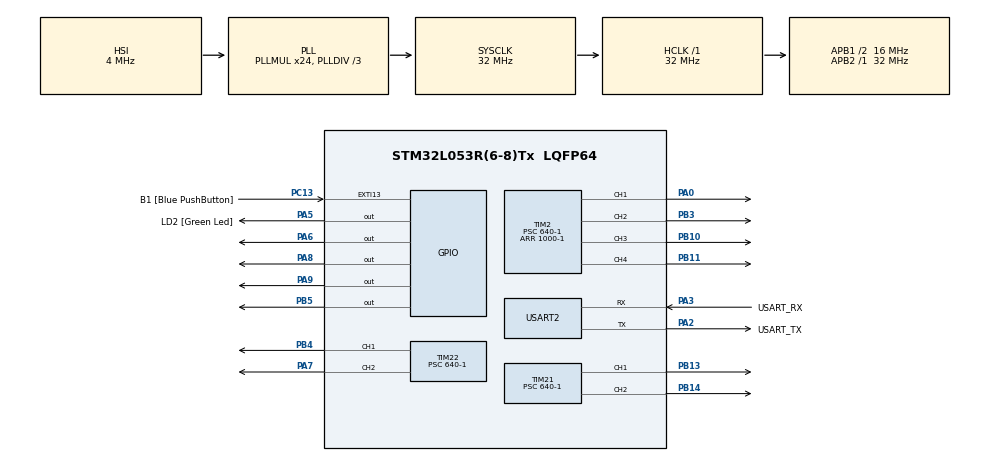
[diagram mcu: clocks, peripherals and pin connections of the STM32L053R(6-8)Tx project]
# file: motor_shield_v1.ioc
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Dma.Request0=USART2_RX
Dma.USART2_RX.0.Direction=DMA_PERIPH_TO_MEMORY
Dma.USART2_RX.0.Instance=DMA1_Channel5
Dma.USART2_RX.0.MemDataAlignment=DMA_MDATAALIGN_BYTE
Dma.USART2_RX.0.MemInc=DMA_MINC_ENABLE
Dma.USART2_RX.0.Mode=DMA_NORMAL
Dma.USART2_RX.0.PeriphDataAlignment=DMA_PDATAALIGN_BYTE
Dma.USART2_RX.0.PeriphInc=DMA_PINC_DISABLE
Dma.USART2_RX.0.Priority=DMA_PRIORITY_LOW
Mcu.Family=STM32L0
Mcu.Name=STM32L053R(6-8)Tx
Mcu.Package=LQFP64
NVIC.DMA1_Channel4_5_6_7_IRQn=true\:0\:0\:false\:false\:true\:false\:true\:true
NVIC.USART2_IRQn=true\:0\:0\:false\:false\:true\:true\:true\:true
PA0.Signal=S_TIM2_CH1
PA13.GPIO_Label=TMS
PA13.Mode=Serial_Wire
PA13.Signal=SYS_SWDIO
PA14.GPIO_Label=TCK
PA14.Mode=Serial_Wire
PA14.Signal=SYS_SWCLK
PA2.GPIO_Label=USART_TX
PA2.Mode=Asynchronous
PA2.Signal=USART2_TX
PA3.GPIO_Label=USART_RX
PA3.Mode=Asynchronous
PA3.Signal=USART2_RX
PA5.GPIO_Label=LD2 [Green Led]
PA5.Signal=GPIO_Output
PA6.Signal=GPIO_Output
PA7.Signal=S_TIM22_CH2
PA8.Signal=GPIO_Output
PA9.Signal=GPIO_Output
PB10.Signal=S_TIM2_CH3
PB11.Signal=S_TIM2_CH4
PB13.Signal=S_TIM21_CH1
PB14.Signal=S_TIM21_CH2
PB3.Signal=S_TIM2_CH2
PB4.Signal=S_TIM22_CH1
PB5.Signal=GPIO_Output
PC13.GPIO_Label=B1 [Blue PushButton]
PC13.GPIO_ModeDefaultEXTI=GPIO_MODE_IT_FALLING
PC13.Signal=GPXTI13
PC14-OSC32_IN.Mode=LSE-External-Oscillator
PC14-OSC32_IN.Signal=RCC_OSC32_IN
PC15-OSC32_OUT.Mode=LSE-External-Oscillator
PC15-OSC32_OUT.Signal=RCC_OSC32_OUT
PH0-OSC_IN.Mode=HSE-External-Clock-Source
PH0-OSC_IN.Signal=RCC_OSC_IN
PH1-OSC_OUT.Signal=RCC_OSC_OUT
ProjectManager.HeapSize=0x200
ProjectManager.StackSize=0x800
ProjectManager.TargetToolchain=MDK-ARM V5.32
RCC.ADCFreq_Value=4000000
RCC.AHBFreq_Value=32000000
RCC.APB1CLKDivider=RCC_HCLK_DIV2
RCC.APB1Freq_Value=16000000
RCC.APB1TimFreq_Value=32000000
RCC.APB2Freq_Value=32000000
RCC.APB2TimFreq_Value=32000000
RCC.HCLKFreq_Value=32000000
RCC.HSE_VALUE=8000000
RCC.HSI16_VALUE=16000000
RCC.HSI48_VALUE=48000000
RCC.HSIRCDiv=4
RCC.HSI_VALUE=4000000
RCC.MSI_VALUE=2097000
RCC.PLLDIV=RCC_PLLDIV_3
RCC.PLLMUL=RCC_PLLMUL_24
RCC.SYSCLKFreq_VALUE=32000000
RCC.SYSCLKSource=RCC_SYSCLKSOURCE_PLLCLK
RCC.VCOOutputFreq_Value=96000000
SH.S_TIM21_CH1.0=TIM21_CH1,PWM Generation1 CH1
SH.S_TIM21_CH2.0=TIM21_CH2,PWM Generation2 CH2
SH.S_TIM22_CH1.0=TIM22_CH1,PWM Generation1 CH1
SH.S_TIM22_CH2.0=TIM22_CH2,PWM Generation2 CH2
SH.S_TIM2_CH1.0=TIM2_CH1,PWM Generation1 CH1
SH.S_TIM2_CH2.0=TIM2_CH2,PWM Generation2 CH2
SH.S_TIM2_CH3.0=TIM2_CH3,PWM Generation3 CH3
SH.S_TIM2_CH4.0=TIM2_CH4,PWM Generation4 CH4
TIM2.Channel-PWM\ Generation1\ CH1=TIM_CHANNEL_1
TIM2.Channel-PWM\ Generation2\ CH2=TIM_CHANNEL_2
TIM2.Channel-PWM\ Generation3\ CH3=TIM_CHANNEL_3
TIM2.Channel-PWM\ Generation4\ CH4=TIM_CHANNEL_4
TIM2.Period=1000-1
TIM2.Prescaler=640-1
TIM21.Channel-PWM\ Generation1\ CH1=TIM_CHANNEL_1
TIM21.Channel-PWM\ Generation2\ CH2=TIM_CHANNEL_2
TIM21.Period=1000-1
TIM21.Prescaler=640-1
TIM22.Channel-PWM\ Generation1\ CH1=TIM_CHANNEL_1
TIM22.Channel-PWM\ Generation2\ CH2=TIM_CHANNEL_2
TIM22.Period=1000-1
TIM22.Prescaler=640-1
USART2.VirtualMode-Asynchronous=VM_ASYNC
VP_TIM21_VS_ClockSourceINT.Mode=Internal
VP_TIM22_VS_ClockSourceINT.Mode=Internal
VP_TIM2_VS_ClockSourceINT.Mode=Internal
board=NUCLEO-L053R8

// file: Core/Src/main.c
/* USER CODE BEGIN Header */
/**
  ******************************************************************************
  * @file           : main.c
  * @brief          : Main program body
  ******************************************************************************
  * @attention
  *
  * Copyright (c) 2023 STMicroelectronics.
  * All rights reserved.
  *
  * This software is licensed under terms that can be found in the LICENSE file
  * in the root directory of this software component.
  * If no LICENSE file comes with this software, it is provided AS-IS.
  *
  ******************************************************************************
  */
/* USER CODE END Header */
#include "main.h"
#include "dma.h"
#include "tim.h"
#include "usart.h"
#include "gpio.h"

void SystemClock_Config(void);

int main(void)
{

  /* MCU Configuration--------------------------------------------------------*/

  /* Reset of all peripherals, Initializes the Flash interface and the Systick. */
  HAL_Init();

  /* Configure the system clock */
  SystemClock_Config();

  /* Initialize all configured peripherals */
  MX_GPIO_Init();
  MX_DMA_Init();
  MX_USART2_UART_Init();
  MX_TIM2_Init();
  MX_TIM22_Init();
  MX_TIM21_Init();
  /* USER CODE BEGIN 2 */
	HAL_UARTEx_ReceiveToIdle_DMA(&huart2, RxBuf, RxBuf_SIZE);
	__HAL_DMA_DISABLE_IT(&hdma_usart2_rx, DMA_IT_HT);
  /* USER CODE END 2 */

  /* Infinite loop */
  /* USER CODE BEGIN WHILE */

	printf("Test start\r\n"); // Print for debug.
	core_config();
	ms_v1_motor_control(&motor_shield_v1,M1,0);
	ms_v1_motor_control(&motor_shield_v1,M2,0);
	ms_v1_motor_control(&motor_shield_v1,M3,0);
	ms_v1_motor_control(&motor_shield_v1,M4,0);

	printf("[Test servo]\r\n"); // Print for debug.

  while (1)
  {
    /* USER CODE END WHILE */

    /* USER CODE BEGIN 3 */
//		for(int i=0; i<=999; i++){
//			ms_v1_motor_control(&motor_shield_v1,M1,i);
//			HAL_Delay(1);
//		}
//		for(int i=999-1; i>=-999; i--){
//			ms_v1_motor_control(&motor_shield_v1,M1,i);
//			HAL_Delay(1);
//		}
//		for(int i=-999+1; i<0; i++){
//			ms_v1_motor_control(&motor_shield_v1,M1,i);
//			HAL_Delay(1);
//		}
  }
  /* USER CODE END 3 */
}

void SystemClock_Config(void)
{
  RCC_OscInitTypeDef RCC_OscInitStruct = {0};
  RCC_ClkInitTypeDef RCC_ClkInitStruct = {0};
  RCC_PeriphCLKInitTypeDef PeriphClkInit = {0};

  /** Configure the main internal regulator output voltage
  */
  __HAL_PWR_VOLTAGESCALING_CONFIG(PWR_REGULATOR_VOLTAGE_SCALE1);

  /** Initializes the RCC Oscillators according to the specified parameters
  * in the RCC_OscInitTypeDef structure.
  */
  RCC_OscInitStruct.OscillatorType = RCC_OSCILLATORTYPE_HSI;
  RCC_OscInitStruct.HSIState = RCC_HSI_DIV4;
  RCC_OscInitStruct.HSICalibrationValue = RCC_HSICALIBRATION_DEFAULT;
  RCC_OscInitStruct.PLL.PLLState = RCC_PLL_ON;
  RCC_OscInitStruct.PLL.PLLSource = RCC_PLLSOURCE_HSI;
  RCC_OscInitStruct.PLL.PLLMUL = RCC_PLLMUL_24;
  RCC_OscInitStruct.PLL.PLLDIV = RCC_PLLDIV_3;
  if (HAL_RCC_OscConfig(&RCC_OscInitStruct) != HAL_OK)
  {
    Error_Handler();
  }

  /** Initializes the CPU, AHB and APB buses clocks
  */
  RCC_ClkInitStruct.ClockType = RCC_CLOCKTYPE_HCLK|RCC_CLOCKTYPE_SYSCLK
                              |RCC_CLOCKTYPE_PCLK1|RCC_CLOCKTYPE_PCLK2;
  RCC_ClkInitStruct.SYSCLKSource = RCC_SYSCLKSOURCE_PLLCLK;
  RCC_ClkInitStruct.AHBCLKDivider = RCC_SYSCLK_DIV1;
  RCC_ClkInitStruct.APB1CLKDivider = RCC_HCLK_DIV2;
  RCC_ClkInitStruct.APB2CLKDivider = RCC_HCLK_DIV1;

  if (HAL_RCC_ClockConfig(&RCC_ClkInitStruct, FLASH_LATENCY_1) != HAL_OK)
  {
    Error_Handler();
  }
  PeriphClkInit.PeriphClockSelection = RCC_PERIPHCLK_USART2;
  PeriphClkInit.Usart2ClockSelection = RCC_USART2CLKSOURCE_PCLK1;
  if (HAL_RCCEx_PeriphCLKConfig(&PeriphClkInit) != HAL_OK)
  {
    Error_Handler();
  }
}

void Error_Handler(void)
{
  __disable_irq();
  while (1)
  {
  }
}
